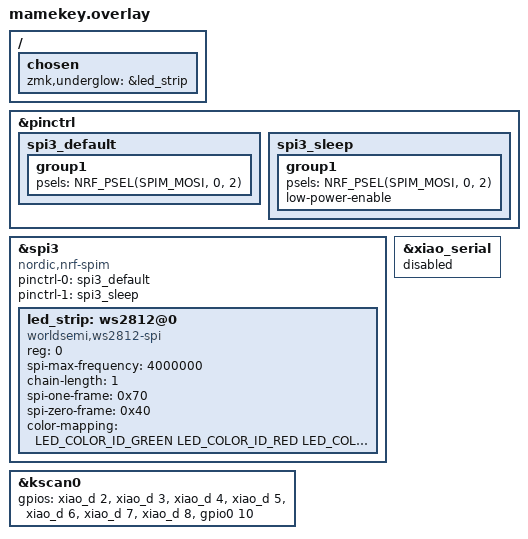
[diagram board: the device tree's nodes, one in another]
#include "mamekey.dtsi"
#include <dt-bindings/led/led.h>


&pinctrl {
    spi3_default: spi3_default {
        group1 {
            psels = <NRF_PSEL(SPIM_MOSI, 0, 2)>;
        };
    };

    spi3_sleep: spi3_sleep {
        group1 {
            psels = <NRF_PSEL(SPIM_MOSI, 0, 2)>;
            low-power-enable;
        };
    };
};

&spi3 {
    compatible = "nordic,nrf-spim";
    status = "okay";

    pinctrl-0 = <&spi3_default>;
    pinctrl-1 = <&spi3_sleep>;
    pinctrl-names = "default", "sleep";

    led_strip: ws2812@0 {
        compatible = "worldsemi,ws2812-spi";

        /* SPI */
        reg = <0>; /* ignored, but necessary for SPI bindings */
        spi-max-frequency = <4000000>;

        /* WS2812 */
        chain-length = <1>; /* number of LEDs */
        spi-one-frame = <0x70>;
        spi-zero-frame = <0x40>;
        color-mapping = <LED_COLOR_ID_GREEN
                         LED_COLOR_ID_RED
                         LED_COLOR_ID_BLUE>;
    };
};

    &kscan0 {
        gpios
          = <&xiao_d 2 GPIO_ACTIVE_HIGH>
          , <&xiao_d 3 GPIO_ACTIVE_HIGH>
          , <&xiao_d 4 GPIO_ACTIVE_HIGH>
          , <&xiao_d 5 GPIO_ACTIVE_HIGH>
          , <&xiao_d 6 GPIO_ACTIVE_HIGH>
          , <&xiao_d 7 GPIO_ACTIVE_HIGH>
          , <&xiao_d 8 GPIO_ACTIVE_HIGH>
          , <&gpio0 10 GPIO_ACTIVE_HIGH>
          ; 
};

/ {
    chosen {
        zmk,underglow = &led_strip;
    };
};

&xiao_serial { status = "disabled"; };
